AUTOSAR XML (schema 4-2-2)
package /Components
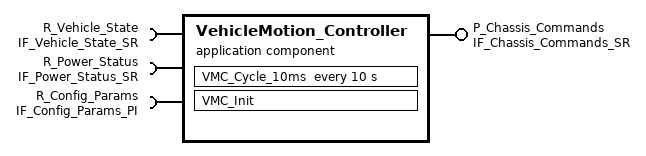
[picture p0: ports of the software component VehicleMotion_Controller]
  application sw component type VehicleMotion_Controller
    provide port P_Chassis_Commands: provided-interface=IF_Chassis_Commands_SR
    require port R_Vehicle_State: required-interface=IF_Vehicle_State_SR
    require port R_Power_Status: required-interface=IF_Power_Status_SR
    require port R_Config_Params: required-interface=IF_Config_Params_PI
    behavior VehicleMotion_Controller_InternalBehavior
      data received event VMC_PowerStatus_Update: start-on-event=VMC_Cycle_10ms
      init event VMC_InitEvent: start-on-event=VMC_Init
      timing event VMC_Cyclic_10ms: start-on-event=VMC_Cycle_10ms, period=10
      runnable VMC_Init
        data-receive-point-by-arguments:
          access Read_Vehicle_Speed_Init: accessed-variable=R_Vehicle_State.vehicle_speed
          access Read_Steering_Angle_Init: accessed-variable=R_Vehicle_State.steering_angle
        data-send-points:
          access Send_Torque_Request_Init: accessed-variable=P_Chassis_Commands.torque_request
          access Send_Steering_Cmd_Init: accessed-variable=P_Chassis_Commands.steering_cmd
        parameter access Access_Controller_Gains_Init: accessed-parameter=R_Config_Params.controller_gains
        parameter access Access_Limits_Init: accessed-parameter=R_Config_Params.limits
        parameter access Access_Security_Policy_Init: accessed-parameter=R_Config_Params.security_policy
      runnable VMC_Cycle_10ms: minimum-start-interval=10
        data-receive-point-by-arguments:
          8 x access:
            Read_Vehicle_Speed_Cycle: accessed-variable=R_Vehicle_State.vehicle_speed
            Read_Yaw_Rate_Cycle: accessed-variable=R_Vehicle_State.yaw_rate
            Read_Longitudinal_Accel_Cycle: accessed-variable=R_Vehicle_State.longitudinal_accel
            Read_Steering_Angle_Cycle: accessed-variable=R_Vehicle_State.steering_angle
            Read_SOC_Cycle: accessed-variable=R_Power_Status.soc
            Read_Power_Available_Cycle: accessed-variable=R_Power_Status.power_available
            Read_Regen_Limit_Cycle: accessed-variable=R_Power_Status.regen_limit
            Read_Thermal_Derate_Cycle: accessed-variable=R_Power_Status.thermal_derate
        data-send-points:
          4 x access:
            Send_Torque_Request_Cycle: accessed-variable=P_Chassis_Commands.torque_request
            Send_Brake_Pressure_Cmd_Cycle: accessed-variable=P_Chassis_Commands.brake_pressure_cmd
            Send_Steering_Cmd_Cycle: accessed-variable=P_Chassis_Commands.steering_cmd
            Send_Suspension_Mode_Cycle: accessed-variable=P_Chassis_Commands.suspension_mode
        parameter access Access_Limits_Cycle: accessed-parameter=R_Config_Params.limits
        parameter access Access_Controller_Gains_Cycle: accessed-parameter=R_Config_Params.controller_gains
